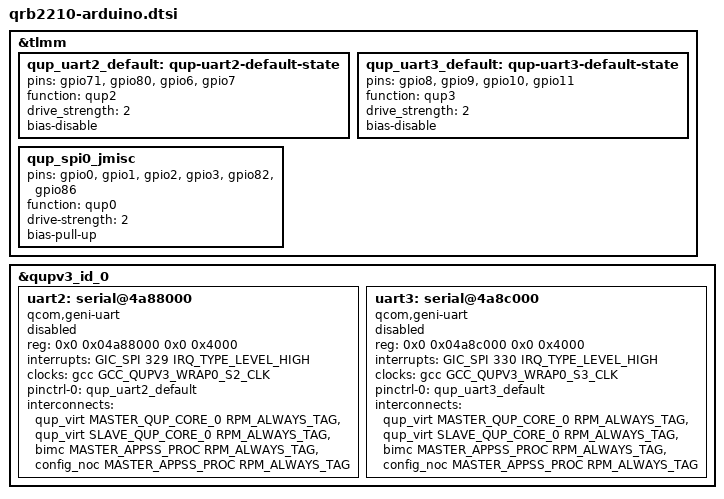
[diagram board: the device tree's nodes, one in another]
// SPDX-License-Identifier: (GPL-2.0+ OR BSD-3-Clause)
/*
 * Copyright (c) 2025, Arduino SA
 */

#include "qcm2290.dtsi"

&tlmm {
    qup_uart2_default: qup-uart2-default-state {
		pins = "gpio71", "gpio80", "gpio6", "gpio7";
		function = "qup2";
		drive_strength = <2>;
		bias-disable;
	};

	qup_uart3_default: qup-uart3-default-state {
		pins = "gpio8","gpio9","gpio10", "gpio11";
		function = "qup3";
		drive_strength = <2>;
		bias-disable;
	};

	qup_spi0_jmisc: qup_spi0_jmisc {
		pins = "gpio0", "gpio1","gpio2", "gpio3", "gpio82", "gpio86";
		function = "qup0";
		drive-strength = <2>;
		bias-pull-up;
	};
};


&qupv3_id_0 {
	uart2: serial@4a88000 {
		compatible = "qcom,geni-uart";
		reg = <0x0 0x04a88000 0x0 0x4000>;
		interrupts = <GIC_SPI 329 IRQ_TYPE_LEVEL_HIGH>;
		clocks = <&gcc GCC_QUPV3_WRAP0_S2_CLK>;
		clock-names = "se";
		pinctrl-0 = <&qup_uart2_default>;
		pinctrl-names = "default";
		interconnects = <&qup_virt MASTER_QUP_CORE_0 RPM_ALWAYS_TAG
						 &qup_virt SLAVE_QUP_CORE_0 RPM_ALWAYS_TAG>,
						<&bimc MASTER_APPSS_PROC RPM_ALWAYS_TAG
						 &config_noc MASTER_APPSS_PROC RPM_ALWAYS_TAG>;
		interconnect-names = "qup-core",
						     "qup-config";
		status = "disabled";
	};

	uart3: serial@4a8c000 {
		compatible = "qcom,geni-uart";
		reg = <0x0 0x04a8c000 0x0 0x4000>;
		interrupts = <GIC_SPI 330 IRQ_TYPE_LEVEL_HIGH>;
		clocks = <&gcc GCC_QUPV3_WRAP0_S3_CLK>;
		clock-names = "se";
		pinctrl-0 = <&qup_uart3_default>;
		pinctrl-names = "default";
		interconnects = <&qup_virt MASTER_QUP_CORE_0 RPM_ALWAYS_TAG
						 &qup_virt SLAVE_QUP_CORE_0 RPM_ALWAYS_TAG>,
						<&bimc MASTER_APPSS_PROC RPM_ALWAYS_TAG
						 &config_noc MASTER_APPSS_PROC RPM_ALWAYS_TAG>;
		interconnect-names = "qup-core",
						     "qup-config";
		status = "disabled";
	};
};
